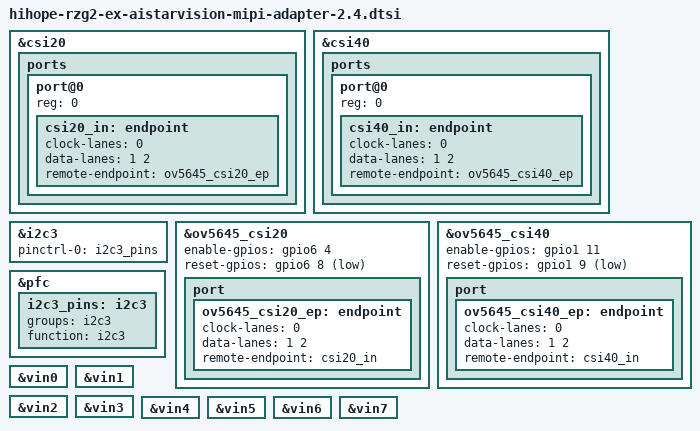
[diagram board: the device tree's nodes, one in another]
// SPDX-License-Identifier: GPL-2.0
/*
 * Device Tree Source for the HiHope RZ/G2[HMN] MIPI common parts
 *
 * Copyright (C) 2021 Renesas Electronics Corp.
 */

#define MIPI_OV5645_PARENT_I2C_CSI20 i2c2
#define MIPI_OV5645_PARENT_I2C_CSI40 i2c3
#include "aistarvision-mipi-adapter-2.4.dtsi"

&csi20 {
	status = "okay";

	ports {
		port@0 {
			reg = <0>;
			csi20_in: endpoint {
				clock-lanes = <0>;
				data-lanes = <1 2>;
				remote-endpoint = <&ov5645_csi20_ep>;
			};
		};
	};
};

&csi40 {
	status = "okay";

	ports {
		port@0 {
			reg = <0>;
			csi40_in: endpoint {
				clock-lanes = <0>;
				data-lanes = <1 2>;
				remote-endpoint = <&ov5645_csi40_ep>;
			};
		};
	};
};

&i2c3 {
	pinctrl-0 = <&i2c3_pins>;
	pinctrl-names = "default";
	status = "okay";
};

&ov5645_csi20 {
	enable-gpios = <&gpio6 4 GPIO_ACTIVE_HIGH>;
	reset-gpios = <&gpio6 8 GPIO_ACTIVE_LOW>;

	port {
		ov5645_csi20_ep: endpoint {
			clock-lanes = <0>;
			data-lanes = <1 2>;
			remote-endpoint = <&csi20_in>;
		};
	};
};

&ov5645_csi40 {
	enable-gpios = <&gpio1 11 GPIO_ACTIVE_HIGH>;
	reset-gpios = <&gpio1 9 GPIO_ACTIVE_LOW>;

	port {
		ov5645_csi40_ep: endpoint {
			clock-lanes = <0>;
			data-lanes = <1 2>;
			remote-endpoint = <&csi40_in>;
		};
	};
};

&pfc {
	i2c3_pins: i2c3 {
		groups = "i2c3";
		function = "i2c3";
	};
};

&vin0 {
	status = "okay";
};

&vin1 {
	status = "okay";
};

&vin2 {
	status = "okay";
};

&vin3 {
	status = "okay";
};

&vin4 {
	status = "okay";
};

&vin5 {
	status = "okay";
};

&vin6 {
	status = "okay";
};

&vin7 {
	status = "okay";
};
